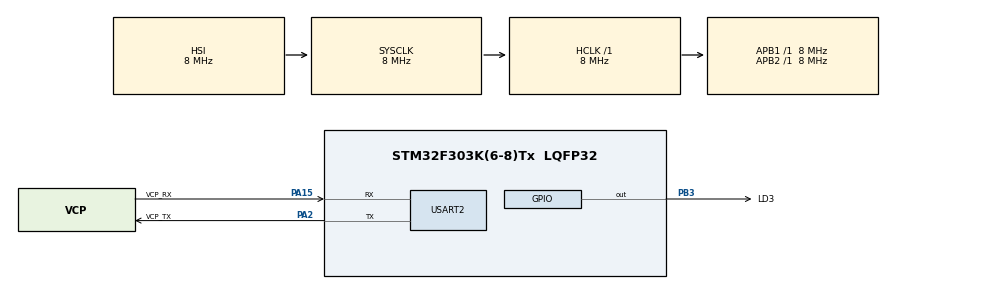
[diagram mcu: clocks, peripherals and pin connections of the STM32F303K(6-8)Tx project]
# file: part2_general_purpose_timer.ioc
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Mcu.Family=STM32F3
Mcu.Name=STM32F303K(6-8)Tx
Mcu.Package=LQFP32
NVIC.PriorityGroup=NVIC_PRIORITYGROUP_4
PA13.GPIO_Label=SWDIO
PA13.Mode=Serial_Wire
PA13.Signal=SYS_JTMS-SWDIO
PA14.GPIO_Label=SWCLK
PA14.Mode=Serial_Wire
PA14.Signal=SYS_JTCK-SWCLK
PA15.GPIO_Label=VCP_RX
PA15.Mode=Asynchronous
PA15.Signal=USART2_RX
PA2.GPIO_Label=VCP_TX
PA2.Mode=Asynchronous
PA2.Signal=USART2_TX
PB3.GPIO_Label=LD3
PB3.Signal=GPIO_Output
PF0\ /\ OSC_IN.GPIO_Label=MCO
PF0\ /\ OSC_IN.Mode=HSE-External-Clock-Source
PF0\ /\ OSC_IN.Signal=RCC_OSC_IN
ProjectManager.HeapSize=0x200
ProjectManager.StackSize=0x400
ProjectManager.TargetToolchain=STM32CubeIDE
RCC.AHBFreq_Value=8000000
RCC.APB1Freq_Value=8000000
RCC.APB2Freq_Value=8000000
RCC.CortexFreq_Value=8000000
RCC.HSE_VALUE=8000000
RCC.HSI_VALUE=8000000
RCC.SYSCLKFreq_VALUE=8000000
TIM1.Prescaler=8 - 1
USART2.VirtualMode-Asynchronous=VM_ASYNC
VP_TIM1_VS_ClockSourceINT.Mode=Internal
board=NUCLEO-F303K8

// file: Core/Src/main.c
/* USER CODE BEGIN Header */
/**
  ******************************************************************************
  * @file           : main.c
  * @brief          : Main program body
  ******************************************************************************
  * @attention
  *
  * Copyright (c) 2024 STMicroelectronics.
  * All rights reserved.
  *
  * This software is licensed under terms that can be found in the LICENSE file
  * in the root directory of this software component.
  * If no LICENSE file comes with this software, it is provided AS-IS.
  *
  ******************************************************************************
  */
/* USER CODE END Header */
#include "main.h"

/* USER CODE BEGIN Includes */
#include <stdio.h>
#include <stdint.h>
#include <string.h>

/* USER CODE END Includes */

TIM_HandleTypeDef htim1;

UART_HandleTypeDef huart2;

void SystemClock_Config(void);
static void MX_GPIO_Init(void);
static void MX_USART2_UART_Init(void);
static void MX_TIM1_Init(void);

int main(void)
{

  /* MCU Configuration--------------------------------------------------------*/

  /* Reset of all peripherals, Initializes the Flash interface and the Systick. */
  HAL_Init();

  /* Configure the system clock */
  SystemClock_Config();

  /* Initialize all configured peripherals */
  MX_GPIO_Init();
  MX_USART2_UART_Init();
  MX_TIM1_Init();
  /* USER CODE BEGIN 2 */

  HAL_TIM_Base_Start(&htim1);
  uint32_t start_time = 0;
  uint32_t end_time = 0;
  char uart_tx_buf[UART_TX_BUF_LEN] = { 0 };

  /* USER CODE END 2 */

  /* Infinite loop */
  while (1)
  {

    /* USER CODE BEGIN 3 */

    // Get LED toggle time
    start_time = TIM1->CNT;

    HAL_GPIO_TogglePin(LD3_GPIO_Port, LD3_Pin);
    HAL_Delay(LED_TOGGLE_DELAY);

    end_time = TIM1->CNT;

    // Timer rollover/overflow
    if (end_time < start_time) {
      end_time += (1 << 16); // add 16-bit roll-over offset
    }

    // Transmit time elapsed
    sprintf(uart_tx_buf, "Time elapsed: %lu us\r\n", (end_time - start_time));
    HAL_UART_Transmit(&huart2, (uint8_t*)uart_tx_buf, strlen(uart_tx_buf), HAL_MAX_DELAY);

    // Reset variables
    memset(uart_tx_buf, 0 , UART_TX_BUF_LEN);
  }
  /* USER CODE END 3 */
}

void SystemClock_Config(void)
{
  RCC_OscInitTypeDef RCC_OscInitStruct = {0};
  RCC_ClkInitTypeDef RCC_ClkInitStruct = {0};
  RCC_PeriphCLKInitTypeDef PeriphClkInit = {0};

  /** Initializes the RCC Oscillators according to the specified parameters
  * in the RCC_OscInitTypeDef structure.
  */
  RCC_OscInitStruct.OscillatorType = RCC_OSCILLATORTYPE_HSI;
  RCC_OscInitStruct.HSIState = RCC_HSI_ON;
  RCC_OscInitStruct.HSICalibrationValue = RCC_HSICALIBRATION_DEFAULT;
  RCC_OscInitStruct.PLL.PLLState = RCC_PLL_NONE;
  if (HAL_RCC_OscConfig(&RCC_OscInitStruct) != HAL_OK)
  {
    Error_Handler();
  }

  /** Initializes the CPU, AHB and APB buses clocks
  */
  RCC_ClkInitStruct.ClockType = RCC_CLOCKTYPE_HCLK|RCC_CLOCKTYPE_SYSCLK
                              |RCC_CLOCKTYPE_PCLK1|RCC_CLOCKTYPE_PCLK2;
  RCC_ClkInitStruct.SYSCLKSource = RCC_SYSCLKSOURCE_HSI;
  RCC_ClkInitStruct.AHBCLKDivider = RCC_SYSCLK_DIV1;
  RCC_ClkInitStruct.APB1CLKDivider = RCC_HCLK_DIV1;
  RCC_ClkInitStruct.APB2CLKDivider = RCC_HCLK_DIV1;

  if (HAL_RCC_ClockConfig(&RCC_ClkInitStruct, FLASH_LATENCY_0) != HAL_OK)
  {
    Error_Handler();
  }
  PeriphClkInit.PeriphClockSelection = RCC_PERIPHCLK_TIM1;
  PeriphClkInit.Tim1ClockSelection = RCC_TIM1CLK_HCLK;
  if (HAL_RCCEx_PeriphCLKConfig(&PeriphClkInit) != HAL_OK)
  {
    Error_Handler();
  }
}

static void MX_TIM1_Init(void)
{

  TIM_ClockConfigTypeDef sClockSourceConfig = {0};
  TIM_MasterConfigTypeDef sMasterConfig = {0};

  htim1.Instance = TIM1;
  htim1.Init.Prescaler = 8 - 1;
  htim1.Init.CounterMode = TIM_COUNTERMODE_UP;
  htim1.Init.Period = 65535;
  htim1.Init.ClockDivision = TIM_CLOCKDIVISION_DIV1;
  htim1.Init.RepetitionCounter = 0;
  htim1.Init.AutoReloadPreload = TIM_AUTORELOAD_PRELOAD_DISABLE;
  if (HAL_TIM_Base_Init(&htim1) != HAL_OK)
  {
    Error_Handler();
  }
  sClockSourceConfig.ClockSource = TIM_CLOCKSOURCE_INTERNAL;
  if (HAL_TIM_ConfigClockSource(&htim1, &sClockSourceConfig) != HAL_OK)
  {
    Error_Handler();
  }
  sMasterConfig.MasterOutputTrigger = TIM_TRGO_RESET;
  sMasterConfig.MasterOutputTrigger2 = TIM_TRGO2_RESET;
  sMasterConfig.MasterSlaveMode = TIM_MASTERSLAVEMODE_DISABLE;
  if (HAL_TIMEx_MasterConfigSynchronization(&htim1, &sMasterConfig) != HAL_OK)
  {
    Error_Handler();
  }

}

static void MX_USART2_UART_Init(void)
{

  huart2.Instance = USART2;
  huart2.Init.BaudRate = 38400;
  huart2.Init.WordLength = UART_WORDLENGTH_8B;
  huart2.Init.StopBits = UART_STOPBITS_1;
  huart2.Init.Parity = UART_PARITY_NONE;
  huart2.Init.Mode = UART_MODE_TX_RX;
  huart2.Init.HwFlowCtl = UART_HWCONTROL_NONE;
  huart2.Init.OverSampling = UART_OVERSAMPLING_16;
  huart2.Init.OneBitSampling = UART_ONE_BIT_SAMPLE_DISABLE;
  huart2.AdvancedInit.AdvFeatureInit = UART_ADVFEATURE_NO_INIT;
  if (HAL_UART_Init(&huart2) != HAL_OK)
  {
    Error_Handler();
  }

}

static void MX_GPIO_Init(void)
{
  GPIO_InitTypeDef GPIO_InitStruct = {0};

  /* GPIO Ports Clock Enable */
  __HAL_RCC_GPIOF_CLK_ENABLE();
  __HAL_RCC_GPIOA_CLK_ENABLE();
  __HAL_RCC_GPIOB_CLK_ENABLE();

  /*Configure GPIO pin Output Level */
  HAL_GPIO_WritePin(LD3_GPIO_Port, LD3_Pin, GPIO_PIN_RESET);

  /*Configure GPIO pin : LD3_Pin */
  GPIO_InitStruct.Pin = LD3_Pin;
  GPIO_InitStruct.Mode = GPIO_MODE_OUTPUT_PP;
  GPIO_InitStruct.Pull = GPIO_NOPULL;
  GPIO_InitStruct.Speed = GPIO_SPEED_FREQ_LOW;
  HAL_GPIO_Init(LD3_GPIO_Port, &GPIO_InitStruct);

}

void Error_Handler(void)
{
  __disable_irq();
  while (1)
  {
  }
}
